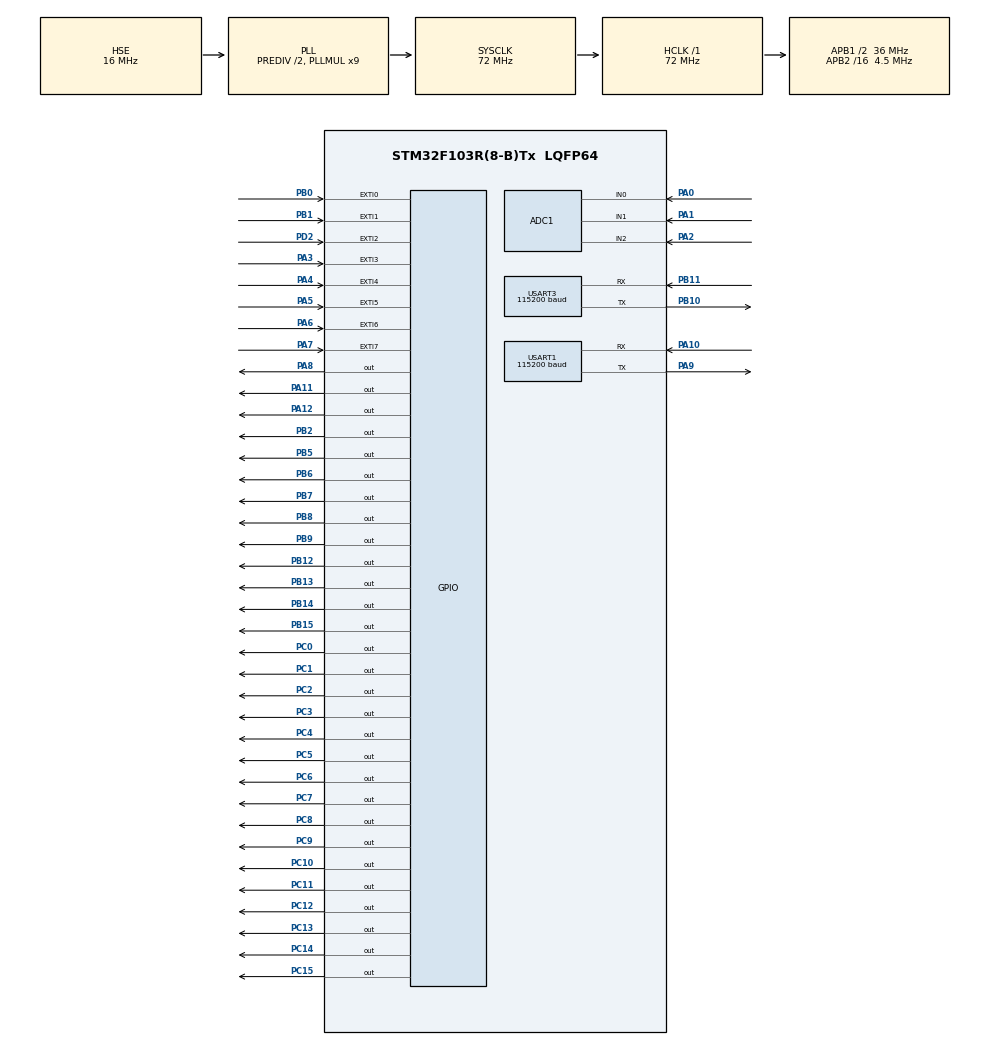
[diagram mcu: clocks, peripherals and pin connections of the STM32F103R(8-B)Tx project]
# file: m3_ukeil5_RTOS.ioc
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Mcu.Family=STM32F1
NVIC.USART3_IRQn=true\:5\:0\:false\:false\:true\:true\:true\:true
NVIC.ADC1_2_IRQn=true\:5\:0\:false\:false\:true\:true\:true\:true
PB10.Mode=Asynchronous
ADC1.ContinuousConvMode=ENABLE
USART1.BaudRate=115200
SH.ADCx_IN2.0=ADC1_IN2,IN2
PC10.Signal=GPIO_Output
PC12.Signal=GPIO_Output
NVIC.EXTI3_IRQn=true\:5\:0\:false\:false\:true\:true\:true\:true
PB11.Signal=USART3_RX
PB13.Signal=GPIO_Output
PB15.Signal=GPIO_Output
RCC.SYSCLKSource=RCC_SYSCLKSOURCE_PLLCLK
ProjectManager.StackSize=0x400
PD1-OSC_OUT.Signal=RCC_OSC_OUT
NVIC.EXTI1_IRQn=true\:5\:0\:false\:false\:true\:true\:true\:true
PA12.Signal=GPIO_Output
TIM1.Prescaler=36000-1
USART3.BaudRate=115200
RCC.HCLKFreq_Value=72000000
RCC.APB2TimFreq_Value=9000000
TIM3.Period=1000-1
PB1.GPIO_ModeDefaultEXTI=GPIO_MODE_IT_RISING
PB6.Signal=GPIO_Output
PC7.Signal=GPIO_Output
PB5.PinState=GPIO_PIN_SET
PC3.Signal=GPIO_Output
RCC.AHBFreq_Value=72000000
RCC.HSE_VALUE=16000000
PB3.Mode=JTAG_5_pins
PB2.Signal=GPIO_Output
PA15.Mode=JTAG_5_pins
RCC.PLLMUL=RCC_PLL_MUL9
PB0.GPIO_ModeDefaultEXTI=GPIO_MODE_IT_RISING
PB4.Mode=JTAG_5_pins
PA14.Mode=JTAG_5_pins
TIM3.Prescaler=72-1
PB8.PinState=GPIO_PIN_SET
PB7.Signal=GPIO_Output
PA8.Signal=GPIO_Output
SH.ADCx_IN0.0=ADC1_IN0,IN0
VP_FREERTOS_VS_CMSIS_V1.Mode=CMSIS_V1
ADC1.Channel-15\#ChannelRegularConversion=ADC_CHANNEL_0
VP_TIM1_VS_ClockSourceINT.Mode=Internal
PB7.PinState=GPIO_PIN_SET
ADC1.Rank-15\#ChannelRegularConversion=1
Mcu.Package=LQFP64
PB9.Signal=GPIO_Output
PB1.Signal=GPXTI1
PA6.Signal=GPXTI6
PA10.Signal=USART1_RX
PA15.Signal=SYS_JTDI
RCC.APB2CLKDivider=RCC_HCLK_DIV16
SH.ADCx_IN1.0=ADC1_IN1,IN1
ADC1.SamplingTime-15\#ChannelRegularConversion=ADC_SAMPLETIME_55CYCLES_5
NVIC.EXTI2_IRQn=true\:5\:0\:false\:false\:true\:true\:true\:true
RCC.APB1TimFreq_Value=72000000
PC5.Signal=GPIO_Output
TIM1.Period=800
NVIC.USART1_IRQn=true\:5\:0\:false\:false\:true\:true\:true\:true
PC0.PinState=GPIO_PIN_RESET
VP_TIM3_VS_ClockSourceINT.Mode=Internal
PB4.Signal=SYS_NJTRST
PA3.Signal=GPXTI3
RCC.PLLSourceVirtual=RCC_PLLSOURCE_HSE
NVIC.EXTI4_IRQn=true\:5\:0\:false\:false\:true\:true\:true\:true
PA5.GPIO_ModeDefaultEXTI=GPIO_MODE_IT_RISING
PA6.GPIO_ModeDefaultEXTI=GPIO_MODE_IT_RISING
FREERTOS.Tasks01=defaultTask,0,128,StartDefaultTask,Default,NULL
PD1-OSC_OUT.Mode=HSE-External-Oscillator
PA10.Mode=Asynchronous
ADC1.SamplingTime-16\#ChannelRegularConversion=ADC_SAMPLETIME_55CYCLES_5
PC11.Signal=GPIO_Output
ADC1.Rank-18\#ChannelRegularConversion=3
PA7.GPIO_ModeDefaultEXTI=GPIO_MODE_IT_RISING
PC8.Signal=GPIO_Output
PC2.Signal=GPIO_Output
PC4.Signal=GPIO_Output
PC6.Signal=GPIO_Output
PC13-TAMPER-RTC.Signal=GPIO_Output
PD0-OSC_IN.Signal=RCC_OSC_IN
PC0.Signal=GPIO_Output
RCC.APB1CLKDivider=RCC_HCLK_DIV2
PC14-OSC32_IN.Signal=GPIO_Output
PA0-WKUP.Signal=ADCx_IN0
PA3.GPIO_ModeDefaultEXTI=GPIO_MODE_IT_RISING
RCC.ADCPresc=RCC_ADCPCLK2_DIV8
PA13.Signal=SYS_JTMS-SWDIO
PA9.Mode=Asynchronous
PB11.Mode=Asynchronous
ProjectManager.TargetToolchain=STM32CubeIDE
ADC1.Channel-18\#ChannelRegularConversion=ADC_CHANNEL_0
PA9.Signal=USART1_TX
PA4.GPIO_ModeDefaultEXTI=GPIO_MODE_IT_RISING
RCC.USBFreq_Value=72000000
PC15-OSC32_OUT.Signal=GPIO_Output
PA1.Signal=ADCx_IN1
PD0-OSC_IN.Mode=HSE-External-Oscillator
PB10.Signal=USART3_TX
PB14.Signal=GPIO_Output
PA5.Signal=GPXTI5
board=custom
NVIC.TIM3_IRQn=true\:5\:0\:false\:false\:true\:true\:true\:true
TIM1.TIM_MasterOutputTrigger=TIM_TRGO_UPDATE
RCC.APB2Freq_Value=4500000
ADC1.Channel-16\#ChannelRegularConversion=ADC_CHANNEL_0
ADC1.NbrOfConversion=3
PA13.Mode=JTAG_5_pins
Mcu.Name=STM32F103R(8-B)Tx
PA2.Signal=ADCx_IN2
ADC1.ExternalTrigConv=ADC_EXTERNALTRIGCONV_T1_CC1
NVIC.TIM1_CC_IRQn=true\:5\:0\:false\:false\:true\:true\:true\:true
PB3.Signal=SYS_JTDO-TRACESWO
NVIC.EXTI0_IRQn=true\:5\:0\:false\:false\:true\:true\:true\:true
PA4.Signal=GPXTI4
RCC.SYSCLKFreq_VALUE=72000000
ADC1.Rank-16\#ChannelRegularConversion=2
PB5.Signal=GPIO_Output
ADC1.master=1
USART3.VirtualMode=VM_ASYNC
RCC.HSEDivPLL=RCC_HSE_PREDIV_DIV2
TIM3.TIM_MasterSlaveMode=TIM_MASTERSLAVEMODE_ENABLE
USART1.VirtualMode=VM_ASYNC
PB6.PinState=GPIO_PIN_SET
PB9.PinState=GPIO_PIN_RESET
PA11.Signal=GPIO_Output
NVIC.EXTI9_5_IRQn=true\:5\:0\:false\:false\:true\:true\:true\:true
PA14.Signal=SYS_JTCK-SWCLK
ProjectManager.HeapSize=0x200
NVIC.PriorityGroup=NVIC_PRIORITYGROUP_4
ADC1.NbrOfConversionFlag=1
PB8.Signal=GPIO_Output
PC9.Signal=GPIO_Output
TIM3.TIM_MasterOutputTrigger=TIM_TRGO_UPDATE
PD2.Signal=GPXTI2
RCC.APB1Freq_Value=36000000
PB0.Signal=GPXTI0
ADC1.SamplingTime-18\#ChannelRegularConversion=ADC_SAMPLETIME_55CYCLES_5
PC1.Signal=GPIO_Output
PB12.Signal=GPIO_Output
TIM1.TIM_MasterSlaveMode=TIM_MASTERSLAVEMODE_ENABLE
PA7.Signal=GPXTI7

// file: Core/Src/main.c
/* USER CODE BEGIN Header */
/**
  ******************************************************************************
  * @file           : main.c
  * @brief          : Main program body
  ******************************************************************************
  * @attention
  *
  * <h2><center>&copy; Copyright (c) 2021 STMicroelectronics.
  * All rights reserved.</center></h2>
  *
  * This software component is licensed by ST under Ultimate Liberty license
  * SLA0044, the "License"; You may not use this file except in compliance with
  * the License. You may obtain a copy of the License at:
  *                             www.st.com/SLA0044
  *
  ******************************************************************************
//  */
/* USER CODE END Header */

#include "main.h"
#include "cmsis_os.h"

ADC_HandleTypeDef hadc1;

TIM_HandleTypeDef htim1;
TIM_HandleTypeDef htim3;

UART_HandleTypeDef huart1;
UART_HandleTypeDef huart3;

osThreadId defaultTaskHandle;
/* USER CODE BEGIN PV */
osThreadId UserTaskHandle;
/* USER CODE END PV */

void SystemClock_Config(void);
static void MX_GPIO_Init(void);
static void MX_USART3_UART_Init(void);
static void MX_ADC1_Init(void);
static void MX_USART1_UART_Init(void);
static void MX_TIM1_Init(void);
static void MX_TIM3_Init(void);
void StartDefaultTask(void const * argument);
void UserTask(void const * argument);

/* USER CODE BEGIN 0 */
void BUZZER_ON_OFF(void)
{
	HAL_GPIO_WritePin(GPIOB, GPIO_PIN_9, GPIO_PIN_SET); HAL_Delay(100);
	HAL_GPIO_WritePin(GPIOB, GPIO_PIN_9, GPIO_PIN_RESET); HAL_Delay(100);
}
/* USER CODE END 0 */

int main(void)
{

  /* MCU Configuration--------------------------------------------------------*/

  /* Reset of all peripherals, Initializes the Flash interface and the Systick. */
  HAL_Init();

  /* Configure the system clock */
  SystemClock_Config();

  /* Initialize all configured peripherals */
  MX_GPIO_Init();
  MX_USART3_UART_Init();
  MX_ADC1_Init();
  MX_USART1_UART_Init();
  MX_TIM1_Init();
  MX_TIM3_Init();

  /* Create the thread(s) */
  /* definition and creation of defaultTask */
  osThreadDef(defaultTask, StartDefaultTask, osPriorityNormal, 0, 128);
  defaultTaskHandle = osThreadCreate(osThread(defaultTask), NULL);

  osThreadDef(UserTask, UserTask, osPriorityNormal, 0, 127);
  UserTaskHandle = osThreadCreate(osThread(UserTask), NULL);

  /* Start scheduler */
  osKernelStart();

  /* We should never get here as control is now taken by the scheduler */

  /* Infinite loop */
  while (1)
  {

  }
}

void SystemClock_Config(void)
{
  RCC_OscInitTypeDef RCC_OscInitStruct = {0};
  RCC_ClkInitTypeDef RCC_ClkInitStruct = {0};
  RCC_PeriphCLKInitTypeDef PeriphClkInit = {0};

  /** Initializes the CPU, AHB and APB busses clocks
  */
  RCC_OscInitStruct.OscillatorType = RCC_OSCILLATORTYPE_HSE;
  RCC_OscInitStruct.HSEState = RCC_HSE_ON;
  RCC_OscInitStruct.HSEPredivValue = RCC_HSE_PREDIV_DIV2;
  RCC_OscInitStruct.HSIState = RCC_HSI_ON;
  RCC_OscInitStruct.PLL.PLLState = RCC_PLL_ON;
  RCC_OscInitStruct.PLL.PLLSource = RCC_PLLSOURCE_HSE;
  RCC_OscInitStruct.PLL.PLLMUL = RCC_PLL_MUL9;
  if (HAL_RCC_OscConfig(&RCC_OscInitStruct) != HAL_OK)
  {
    Error_Handler();
  }
  /** Initializes the CPU, AHB and APB busses clocks
  */
  RCC_ClkInitStruct.ClockType = RCC_CLOCKTYPE_HCLK|RCC_CLOCKTYPE_SYSCLK
                              |RCC_CLOCKTYPE_PCLK1|RCC_CLOCKTYPE_PCLK2;
  RCC_ClkInitStruct.SYSCLKSource = RCC_SYSCLKSOURCE_PLLCLK;
  RCC_ClkInitStruct.AHBCLKDivider = RCC_SYSCLK_DIV1;
  RCC_ClkInitStruct.APB1CLKDivider = RCC_HCLK_DIV2;
  RCC_ClkInitStruct.APB2CLKDivider = RCC_HCLK_DIV16;

  if (HAL_RCC_ClockConfig(&RCC_ClkInitStruct, FLASH_LATENCY_2) != HAL_OK)
  {
    Error_Handler();
  }
  PeriphClkInit.PeriphClockSelection = RCC_PERIPHCLK_ADC;
  PeriphClkInit.AdcClockSelection = RCC_ADCPCLK2_DIV8;
  if (HAL_RCCEx_PeriphCLKConfig(&PeriphClkInit) != HAL_OK)
  {
    Error_Handler();
  }
}

static void MX_ADC1_Init(void)
{

  ADC_ChannelConfTypeDef sConfig = {0};

  /** Common config
  */
  hadc1.Instance = ADC1;
  hadc1.Init.ScanConvMode = ADC_SCAN_ENABLE;
  hadc1.Init.ContinuousConvMode = ENABLE;
  hadc1.Init.DiscontinuousConvMode = DISABLE;
  hadc1.Init.ExternalTrigConv = ADC_EXTERNALTRIGCONV_T1_CC1;
  hadc1.Init.DataAlign = ADC_DATAALIGN_RIGHT;
  hadc1.Init.NbrOfConversion = 3;
  if (HAL_ADC_Init(&hadc1) != HAL_OK)
  {
    Error_Handler();
  }
  /** Configure Regular Channel
  */
  sConfig.Channel = ADC_CHANNEL_0;
  sConfig.Rank = ADC_REGULAR_RANK_1;
  sConfig.SamplingTime = ADC_SAMPLETIME_55CYCLES_5;
  if (HAL_ADC_ConfigChannel(&hadc1, &sConfig) != HAL_OK)
  {
    Error_Handler();
  }
  /** Configure Regular Channel
  */
  sConfig.Rank = ADC_REGULAR_RANK_2;
  if (HAL_ADC_ConfigChannel(&hadc1, &sConfig) != HAL_OK)
  {
    Error_Handler();
  }
  /** Configure Regular Channel
  */
  sConfig.Rank = ADC_REGULAR_RANK_3;
  if (HAL_ADC_ConfigChannel(&hadc1, &sConfig) != HAL_OK)
  {
    Error_Handler();
  }

}

static void MX_TIM1_Init(void)
{

  TIM_ClockConfigTypeDef sClockSourceConfig = {0};
  TIM_MasterConfigTypeDef sMasterConfig = {0};

  htim1.Instance = TIM1;
  htim1.Init.Prescaler = 36000-1;
  htim1.Init.CounterMode = TIM_COUNTERMODE_UP;
  htim1.Init.Period = 800;
  htim1.Init.ClockDivision = TIM_CLOCKDIVISION_DIV1;
  htim1.Init.RepetitionCounter = 0;
  htim1.Init.AutoReloadPreload = TIM_AUTORELOAD_PRELOAD_DISABLE;
  if (HAL_TIM_Base_Init(&htim1) != HAL_OK)
  {
    Error_Handler();
  }
  sClockSourceConfig.ClockSource = TIM_CLOCKSOURCE_INTERNAL;
  if (HAL_TIM_ConfigClockSource(&htim1, &sClockSourceConfig) != HAL_OK)
  {
    Error_Handler();
  }
  sMasterConfig.MasterOutputTrigger = TIM_TRGO_UPDATE;
  sMasterConfig.MasterSlaveMode = TIM_MASTERSLAVEMODE_ENABLE;
  if (HAL_TIMEx_MasterConfigSynchronization(&htim1, &sMasterConfig) != HAL_OK)
  {
    Error_Handler();
  }

}

static void MX_TIM3_Init(void)
{

  TIM_ClockConfigTypeDef sClockSourceConfig = {0};
  TIM_MasterConfigTypeDef sMasterConfig = {0};

  htim3.Instance = TIM3;
  htim3.Init.Prescaler = 72-1;
  htim3.Init.CounterMode = TIM_COUNTERMODE_UP;
  htim3.Init.Period = 1000-1;
  htim3.Init.ClockDivision = TIM_CLOCKDIVISION_DIV1;
  htim3.Init.AutoReloadPreload = TIM_AUTORELOAD_PRELOAD_DISABLE;
  if (HAL_TIM_Base_Init(&htim3) != HAL_OK)
  {
    Error_Handler();
  }
  sClockSourceConfig.ClockSource = TIM_CLOCKSOURCE_INTERNAL;
  if (HAL_TIM_ConfigClockSource(&htim3, &sClockSourceConfig) != HAL_OK)
  {
    Error_Handler();
  }
  sMasterConfig.MasterOutputTrigger = TIM_TRGO_UPDATE;
  sMasterConfig.MasterSlaveMode = TIM_MASTERSLAVEMODE_ENABLE;
  if (HAL_TIMEx_MasterConfigSynchronization(&htim3, &sMasterConfig) != HAL_OK)
  {
    Error_Handler();
  }

}

static void MX_USART1_UART_Init(void)
{

  huart1.Instance = USART1;
  huart1.Init.BaudRate = 115200;
  huart1.Init.WordLength = UART_WORDLENGTH_8B;
  huart1.Init.StopBits = UART_STOPBITS_1;
  huart1.Init.Parity = UART_PARITY_NONE;
  huart1.Init.Mode = UART_MODE_TX_RX;
  huart1.Init.HwFlowCtl = UART_HWCONTROL_NONE;
  huart1.Init.OverSampling = UART_OVERSAMPLING_16;
  if (HAL_UART_Init(&huart1) != HAL_OK)
  {
    Error_Handler();
  }

}

static void MX_USART3_UART_Init(void)
{

  huart3.Instance = USART3;
  huart3.Init.BaudRate = 115200;
  huart3.Init.WordLength = UART_WORDLENGTH_8B;
  huart3.Init.StopBits = UART_STOPBITS_1;
  huart3.Init.Parity = UART_PARITY_NONE;
  huart3.Init.Mode = UART_MODE_TX_RX;
  huart3.Init.HwFlowCtl = UART_HWCONTROL_NONE;
  huart3.Init.OverSampling = UART_OVERSAMPLING_16;
  if (HAL_UART_Init(&huart3) != HAL_OK)
  {
    Error_Handler();
  }

}

static void MX_GPIO_Init(void)
{
  GPIO_InitTypeDef GPIO_InitStruct = {0};

  /* GPIO Ports Clock Enable */
  __HAL_RCC_GPIOC_CLK_ENABLE();
  __HAL_RCC_GPIOD_CLK_ENABLE();
  __HAL_RCC_GPIOA_CLK_ENABLE();
  __HAL_RCC_GPIOB_CLK_ENABLE();

  /*Configure GPIO pin Output Level */
  HAL_GPIO_WritePin(GPIOC, GPIO_PIN_13|GPIO_PIN_14|GPIO_PIN_15|GPIO_PIN_0
                          |GPIO_PIN_1|GPIO_PIN_2|GPIO_PIN_3|GPIO_PIN_4
                          |GPIO_PIN_5|GPIO_PIN_6|GPIO_PIN_7|GPIO_PIN_8
                          |GPIO_PIN_9|GPIO_PIN_10|GPIO_PIN_11|GPIO_PIN_12, GPIO_PIN_RESET);

  /*Configure GPIO pin Output Level */
  HAL_GPIO_WritePin(GPIOB, GPIO_PIN_2|GPIO_PIN_12|GPIO_PIN_13|GPIO_PIN_14
                          |GPIO_PIN_15|GPIO_PIN_9, GPIO_PIN_RESET);

  /*Configure GPIO pin Output Level */
  HAL_GPIO_WritePin(GPIOA, GPIO_PIN_8|GPIO_PIN_11|GPIO_PIN_12, GPIO_PIN_RESET);

  /*Configure GPIO pin Output Level */
  HAL_GPIO_WritePin(GPIOB, GPIO_PIN_5|GPIO_PIN_6|GPIO_PIN_7|GPIO_PIN_8, GPIO_PIN_SET);

  /*Configure GPIO pins : PC13 PC14 PC15 PC0
                           PC1 PC2 PC3 PC4
                           PC5 PC6 PC7 PC8
                           PC9 PC10 PC11 PC12 */
  GPIO_InitStruct.Pin = GPIO_PIN_13|GPIO_PIN_14|GPIO_PIN_15|GPIO_PIN_0
                          |GPIO_PIN_1|GPIO_PIN_2|GPIO_PIN_3|GPIO_PIN_4
                          |GPIO_PIN_5|GPIO_PIN_6|GPIO_PIN_7|GPIO_PIN_8
                          |GPIO_PIN_9|GPIO_PIN_10|GPIO_PIN_11|GPIO_PIN_12;
  GPIO_InitStruct.Mode = GPIO_MODE_OUTPUT_PP;
  GPIO_InitStruct.Pull = GPIO_NOPULL;
  GPIO_InitStruct.Speed = GPIO_SPEED_FREQ_LOW;
  HAL_GPIO_Init(GPIOC, &GPIO_InitStruct);

  /*Configure GPIO pins : PA3 PA4 PA5 PA6
                           PA7 */
  GPIO_InitStruct.Pin = GPIO_PIN_3|GPIO_PIN_4|GPIO_PIN_5|GPIO_PIN_6
                          |GPIO_PIN_7;
  GPIO_InitStruct.Mode = GPIO_MODE_IT_RISING;
  GPIO_InitStruct.Pull = GPIO_NOPULL;
  HAL_GPIO_Init(GPIOA, &GPIO_InitStruct);

  /*Configure GPIO pins : PB0 PB1 */
  GPIO_InitStruct.Pin = GPIO_PIN_0|GPIO_PIN_1;
  GPIO_InitStruct.Mode = GPIO_MODE_IT_RISING;
  GPIO_InitStruct.Pull = GPIO_NOPULL;
  HAL_GPIO_Init(GPIOB, &GPIO_InitStruct);

  /*Configure GPIO pins : PB2 PB12 PB13 PB14
                           PB15 PB5 PB6 PB7
                           PB8 PB9 */
  GPIO_InitStruct.Pin = GPIO_PIN_2|GPIO_PIN_12|GPIO_PIN_13|GPIO_PIN_14
                          |GPIO_PIN_15|GPIO_PIN_5|GPIO_PIN_6|GPIO_PIN_7
                          |GPIO_PIN_8|GPIO_PIN_9;
  GPIO_InitStruct.Mode = GPIO_MODE_OUTPUT_PP;
  GPIO_InitStruct.Pull = GPIO_NOPULL;
  GPIO_InitStruct.Speed = GPIO_SPEED_FREQ_LOW;
  HAL_GPIO_Init(GPIOB, &GPIO_InitStruct);

  /*Configure GPIO pins : PA8 PA11 PA12 */
  GPIO_InitStruct.Pin = GPIO_PIN_8|GPIO_PIN_11|GPIO_PIN_12;
  GPIO_InitStruct.Mode = GPIO_MODE_OUTPUT_PP;
  GPIO_InitStruct.Pull = GPIO_NOPULL;
  GPIO_InitStruct.Speed = GPIO_SPEED_FREQ_LOW;
  HAL_GPIO_Init(GPIOA, &GPIO_InitStruct);

  /*Configure GPIO pin : PD2 */
  GPIO_InitStruct.Pin = GPIO_PIN_2;
  GPIO_InitStruct.Mode = GPIO_MODE_IT_RISING;
  GPIO_InitStruct.Pull = GPIO_NOPULL;
  HAL_GPIO_Init(GPIOD, &GPIO_InitStruct);

  /* EXTI interrupt init*/
  HAL_NVIC_SetPriority(EXTI0_IRQn, 5, 0);
  HAL_NVIC_EnableIRQ(EXTI0_IRQn);

  HAL_NVIC_SetPriority(EXTI1_IRQn, 5, 0);
  HAL_NVIC_EnableIRQ(EXTI1_IRQn);

  HAL_NVIC_SetPriority(EXTI2_IRQn, 5, 0);
  HAL_NVIC_EnableIRQ(EXTI2_IRQn);

  HAL_NVIC_SetPriority(EXTI3_IRQn, 5, 0);
  HAL_NVIC_EnableIRQ(EXTI3_IRQn);

  HAL_NVIC_SetPriority(EXTI4_IRQn, 5, 0);
  HAL_NVIC_EnableIRQ(EXTI4_IRQn);

  HAL_NVIC_SetPriority(EXTI9_5_IRQn, 5, 0);
  HAL_NVIC_EnableIRQ(EXTI9_5_IRQn);

}

void StartDefaultTask(void const * argument)
{

  /* USER CODE BEGIN 5 */
  /* Infinite loop */
  for(;;)
  {
	BUZZER_ON_OFF();
    osDelay(1);
  }
  /* USER CODE END 5 */
}

void UserTask(void const * argument)
{

  /* USER CODE BEGIN 5 */
  /* Infinite loop */
  for(;;)
  {
		for(int jcnt=0;jcnt<40;jcnt++)
		{
					if((jcnt%2)==0)
					{
						 //HAL_GPIO_WritePin(GPIOB, GPIO_PIN_5, GPIO_PIN_RESET); HAL_Delay(50);
						 //HAL_GPIO_WritePin(GPIOB, GPIO_PIN_6, GPIO_PIN_RESET); HAL_Delay(50);
						 //HAL_GPIO_WritePin(GPIOB, GPIO_PIN_7, GPIO_PIN_RESET); HAL_Delay(50);
					}
					else
					{
						 //HAL_GPIO_WritePin(GPIOB, GPIO_PIN_5, GPIO_PIN_SET); HAL_Delay(50);
						 //HAL_GPIO_WritePin(GPIOB, GPIO_PIN_6, GPIO_PIN_SET); HAL_Delay(50);
						 //HAL_GPIO_WritePin(GPIOB, GPIO_PIN_7, GPIO_PIN_SET); HAL_Delay(50);
					}
		}
    osDelay(1);
  }
  /* USER CODE END 5 */
}

void Error_Handler(void)
{
}

/************************ (C) COPYRIGHT STMicroelectronics *****END OF FILE****/
